VERSION ""

NS_ :

BS_:

BU_:

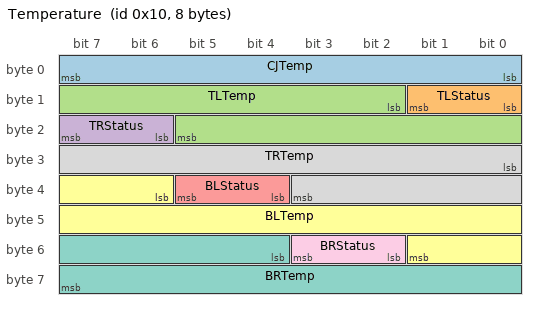
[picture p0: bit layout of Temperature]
BO_ 16 Temperature: 8 Vector__XXX
 SG_ CJTemp : 0|8@1+ (1,-128) [-128|127] "degC" Vector__XXX
 SG_ TLStatus : 8|2@1+ (1,0) [0|3] "" Vector__XXX
 SG_ TLTemp : 10|12@1+ (1,-2048) [-2048|2047] "degC" Vector__XXX
 SG_ TRStatus : 22|2@1+ (1,0) [0|3] "" Vector__XXX
 SG_ BLStatus : 36|2@1+ (1,0) [0|3] "" Vector__XXX
 SG_ BLTemp : 38|12@1+ (1,-2048) [-2048|2047] "degC" Vector__XXX
 SG_ BRTemp : 52|12@1+ (1,-2048) [-2048|2047] "degC" Vector__XXX
 SG_ TRTemp : 24|12@1+ (1,-2048) [-2048|2047] "degC" Vector__XXX
 SG_ BRStatus : 50|2@1+ (1,0) [0|3] "" Vector__XXX

CM_ SG_ 16 CJTemp "Cold junction temperature";
VAL_ 16 TLStatus 0 "OK" 1 "Err1" 2 "Err2" 3 "Err3" ;
VAL_ 16 TRStatus 0 "OK" 1 "Err1" 2 "Err2" 3 "Err3" ;
VAL_ 16 BLStatus 0 "OK" 1 "Err1" 2 "Err2" 3 "Err3" ;
VAL_ 16 BRStatus 0 "OK" 1 "Err1" 2 "Err2" 3 "Err3" ;
